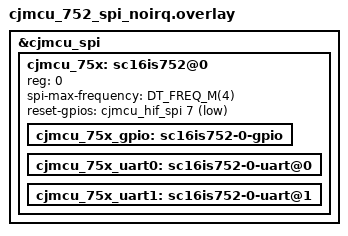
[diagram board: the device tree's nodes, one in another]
/*
 * Copyright (c) 2024 TiaC Systems
 * SPDX-License-Identifier: Apache-2.0
 */

#include <freq.h>
#include <zephyr/dt-bindings/gpio/gpio.h>

&cjmcu_spi {
	status = "okay";

	cjmcu_75x: sc16is752@0 {
		reg = <0>;

		spi-max-frequency = <DT_FREQ_M(4)>;
		reset-gpios = <&cjmcu_hif_spi 7 (GPIO_PULL_UP | GPIO_ACTIVE_LOW)>;

		cjmcu_75x_gpio: sc16is752-0-gpio {};
		cjmcu_75x_uart0: sc16is752-0-uart@0 {};
		cjmcu_75x_uart1: sc16is752-0-uart@1 {};
	};
};

#include "cjmcu_752.dtsi"
